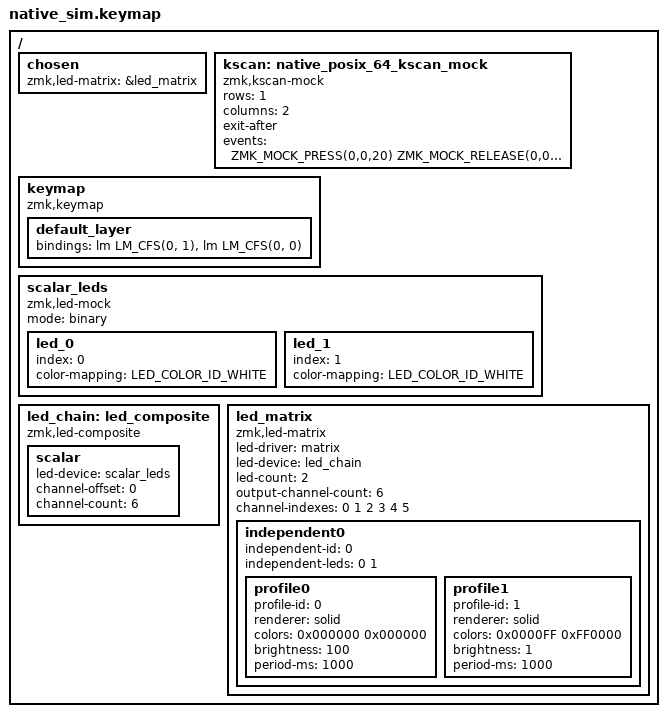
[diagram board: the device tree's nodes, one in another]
#include <dt-bindings/led/led.h>
#include <dt-bindings/zmk/kscan_mock.h>
#include <dt-bindings/zmk/led_matrix.h>
#include <behaviors.dtsi>

/ {
    chosen { zmk,led-matrix = &led_matrix; };

    kscan: native_posix_64_kscan_mock {
        compatible = "zmk,kscan-mock";
        rows = <1>;
        columns = <2>;
        exit-after;
        events = <
            ZMK_MOCK_PRESS(0,0,20)
            ZMK_MOCK_RELEASE(0,0,20)
            ZMK_MOCK_PRESS(0,1,20)
            ZMK_MOCK_RELEASE(0,1,20)
        >;
    };

    keymap {
        compatible = "zmk,keymap";
        default_layer { bindings = <&lm LM_CFS(0, 1) &lm LM_CFS(0, 0)>; };
    };

    scalar_leds: scalar_leds {
        compatible = "zmk,led-mock";
        mode = "binary";
        led_0 { index = <0>; color-mapping = <LED_COLOR_ID_WHITE>; };
        led_1 { index = <1>; color-mapping = <LED_COLOR_ID_WHITE>; };
    };

    led_chain: led_composite {
        compatible = "zmk,led-composite";
        scalar {
            led-device = <&scalar_leds>;
            channel-offset = <0>;
            channel-count = <6>;
        };
    };

    led_matrix: led_matrix {
        compatible = "zmk,led-matrix";
        led-driver = "matrix";
        led-device = <&led_chain>;
        led-count = <2>;
        output-channel-count = <6>;
        channel-indexes = <0 1 2 3 4 5>;

        independent0 {
            independent-id = <0>;
            independent-leds = <0 1>;
            profile0 {
                profile-id = <0>;
                renderer = "solid";
                colors = <0x000000 0x000000>;
                brightness = <100>;
                period-ms = <1000>;
            };
            profile1 {
                profile-id = <1>;
                renderer = "solid";
                colors = <0x0000FF 0xFF0000>;
                brightness = <1>;
                period-ms = <1000>;
            };
        };
    };
};
